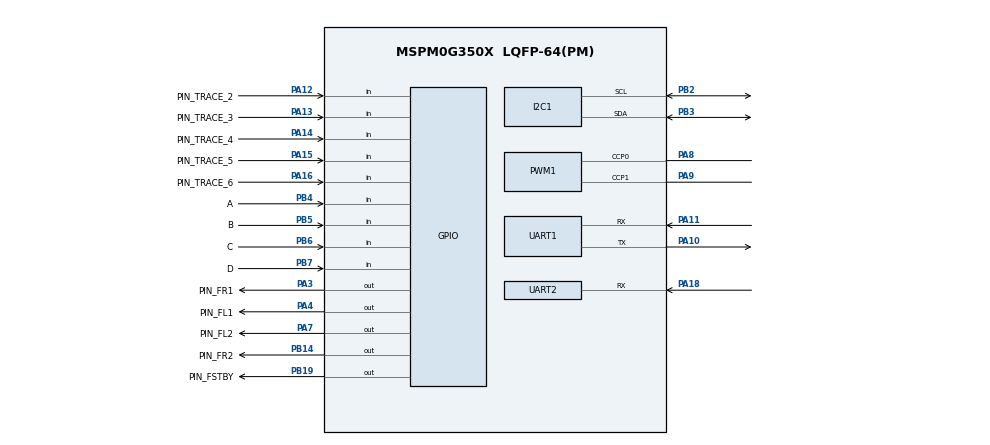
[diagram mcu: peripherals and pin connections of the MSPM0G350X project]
/**
 * These arguments were used when this file was generated. They will be automatically applied on subsequent loads
 * via the GUI or CLI. Run CLI with '--help' for additional information on how to override these arguments.
 * @cliArgs --device "MSPM0G350X" --package "LQFP-64(PM)" --part "Default" --product "mspm0_sdk@2.00.01.00"
 * @versions {"tool":"1.20.0+3587"}
 */

/**
 * Import the modules used in this configuration.
 */
const GPIO   = scripting.addModule("/ti/driverlib/GPIO", {}, false);
const GPIO1  = GPIO.addInstance();
const GPIO2  = GPIO.addInstance();
const GPIO3  = GPIO.addInstance();
const GPIO4  = GPIO.addInstance();
const GPIO5  = GPIO.addInstance();
const I2C    = scripting.addModule("/ti/driverlib/I2C", {}, false);
const I2C1   = I2C.addInstance();
const PWM    = scripting.addModule("/ti/driverlib/PWM", {}, false);
const PWM1   = PWM.addInstance();
const SYSCTL = scripting.addModule("/ti/driverlib/SYSCTL");
const TIMER  = scripting.addModule("/ti/driverlib/TIMER", {}, false);
const TIMER1 = TIMER.addInstance();
const TIMER2 = TIMER.addInstance();
const UART   = scripting.addModule("/ti/driverlib/UART", {}, false);
const UART1  = UART.addInstance();
const UART2  = UART.addInstance();
const UART3  = UART.addInstance();

/**
 * Write custom configuration values to the imported modules.
 */
const divider6       = system.clockTree["PLL_CLK2X_DIV"];
divider6.divideValue = 4;

const divider7       = system.clockTree["PLL_PDIV"];
divider7.divideValue = 2;

const divider9       = system.clockTree["UDIV"];
divider9.divideValue = 2;

const multiplier2         = system.clockTree["PLL_QDIV"];
multiplier2.multiplyValue = 10;

const mux4       = system.clockTree["EXHFMUX"];
mux4.inputSelect = "EXHFMUX_XTAL";

const mux8       = system.clockTree["HSCLKMUX"];
mux8.inputSelect = "HSCLKMUX_SYSPLL0";

const pinFunction4        = system.clockTree["HFXT"];
pinFunction4.enable       = true;
pinFunction4.HFCLKMonitor = true;
pinFunction4.inputFreq    = 40;
pinFunction4.HFXTStartup  = 20;

GPIO1.$name                              = "GPIO_SWITCH";
GPIO1.associatedPins[0].$name            = "USER_SWITCH_S2";
GPIO1.associatedPins[0].direction        = "INPUT";
GPIO1.associatedPins[0].assignedPort     = "PORTB";
GPIO1.associatedPins[0].assignedPin      = "21";
GPIO1.associatedPins[0].internalResistor = "PULL_UP";

const Board = scripting.addModule("/ti/driverlib/Board", {}, false);

GPIO2.$name                         = "GPIO_MOTOR";
GPIO2.associatedPins.create(5);
GPIO2.associatedPins[0].$name       = "PIN_FL2";
GPIO2.associatedPins[0].pin.$assign = "PA7";
GPIO2.associatedPins[1].$name       = "PIN_FL1";
GPIO2.associatedPins[1].pin.$assign = "PA4";
GPIO2.associatedPins[2].$name       = "PIN_FR1";
GPIO2.associatedPins[2].pin.$assign = "PA3";
GPIO2.associatedPins[3].$name       = "PIN_FR2";
GPIO2.associatedPins[3].pin.$assign = "PB14";
GPIO2.associatedPins[4].$name       = "PIN_FSTBY";
GPIO2.associatedPins[4].pin.$assign = "PB19";

GPIO3.$name                         = "GPIO_TRACE";
GPIO3.port                          = "PORTA";
GPIO3.associatedPins.create(8);
GPIO3.associatedPins[0].direction   = "INPUT";
GPIO3.associatedPins[0].$name       = "PIN_TRACE_0";
GPIO3.associatedPins[1].direction   = "INPUT";
GPIO3.associatedPins[1].$name       = "PIN_TRACE_1";
GPIO3.associatedPins[2].direction   = "INPUT";
GPIO3.associatedPins[2].$name       = "PIN_TRACE_2";
GPIO3.associatedPins[2].pin.$assign = "PA12";
GPIO3.associatedPins[3].direction   = "INPUT";
GPIO3.associatedPins[3].$name       = "PIN_TRACE_3";
GPIO3.associatedPins[3].pin.$assign = "PA13";
GPIO3.associatedPins[4].direction   = "INPUT";
GPIO3.associatedPins[4].$name       = "PIN_TRACE_4";
GPIO3.associatedPins[4].pin.$assign = "PA14";
GPIO3.associatedPins[5].direction   = "INPUT";
GPIO3.associatedPins[5].$name       = "PIN_TRACE_5";
GPIO3.associatedPins[5].pin.$assign = "PA15";
GPIO3.associatedPins[6].direction   = "INPUT";
GPIO3.associatedPins[6].$name       = "PIN_TRACE_6";
GPIO3.associatedPins[6].pin.$assign = "PA16";
GPIO3.associatedPins[7].direction   = "INPUT";
GPIO3.associatedPins[7].$name       = "PIN_TRACE_7";

GPIO4.$name                         = "GPIO_GW";
GPIO4.port                          = "PORTA";
GPIO4.associatedPins.create(2);
GPIO4.associatedPins[0].ioStructure = "OD";
GPIO4.associatedPins[0].$name       = "GPIO_SCL";
GPIO4.associatedPins[1].$name       = "GPIO_SDA";
GPIO4.associatedPins[1].ioStructure = "OD";

GPIO5.$name                               = "Encoder";
GPIO5.associatedPins.create(4);
GPIO5.associatedPins[0].direction         = "INPUT";
GPIO5.associatedPins[0].interruptEn       = true;
GPIO5.associatedPins[0].interruptPriority = "1";
GPIO5.associatedPins[0].polarity          = "RISE_FALL";
GPIO5.associatedPins[0].assignedPort      = "PORTB";
GPIO5.associatedPins[0].$name             = "A";
GPIO5.associatedPins[0].pin.$assign       = "PB4";
GPIO5.associatedPins[1].direction         = "INPUT";
GPIO5.associatedPins[1].interruptEn       = true;
GPIO5.associatedPins[1].interruptPriority = "1";
GPIO5.associatedPins[1].polarity          = "RISE_FALL";
GPIO5.associatedPins[1].assignedPort      = "PORTB";
GPIO5.associatedPins[1].$name             = "B";
GPIO5.associatedPins[1].pin.$assign       = "PB5";
GPIO5.associatedPins[2].direction         = "INPUT";
GPIO5.associatedPins[2].interruptEn       = true;
GPIO5.associatedPins[2].interruptPriority = "1";
GPIO5.associatedPins[2].polarity          = "RISE_FALL";
GPIO5.associatedPins[2].assignedPort      = "PORTB";
GPIO5.associatedPins[2].$name             = "C";
GPIO5.associatedPins[2].pin.$assign       = "PB6";
GPIO5.associatedPins[3].direction         = "INPUT";
GPIO5.associatedPins[3].assignedPort      = "PORTB";
GPIO5.associatedPins[3].interruptEn       = true;
GPIO5.associatedPins[3].interruptPriority = "1";
GPIO5.associatedPins[3].polarity          = "RISE_FALL";
GPIO5.associatedPins[3].$name             = "D";
GPIO5.associatedPins[3].pin.$assign       = "PB7";

I2C1.$name                             = "I2C_MPU6050";
I2C1.basicEnableController             = true;
I2C1.intController                     = ["ARBITRATION_LOST","NACK","RXFIFO_TRIGGER","RX_DONE","TX_DONE"];
I2C1.peripheral.$assign                = "I2C1";
I2C1.peripheral.sdaPin.$assign         = "PB3";
I2C1.peripheral.sclPin.$assign         = "PB2";
I2C1.sdaPinConfig.$name                = "ti_driverlib_gpio_GPIOPinGeneric0";
I2C1.sdaPinConfig.hideOutputInversion  = scripting.forceWrite(false);
I2C1.sdaPinConfig.onlyInternalResistor = scripting.forceWrite(false);
I2C1.sdaPinConfig.passedPeripheralType = scripting.forceWrite("Digital");
I2C1.sclPinConfig.$name                = "ti_driverlib_gpio_GPIOPinGeneric1";
I2C1.sclPinConfig.hideOutputInversion  = scripting.forceWrite(false);
I2C1.sclPinConfig.onlyInternalResistor = scripting.forceWrite(false);
I2C1.sclPinConfig.passedPeripheralType = scripting.forceWrite("Digital");

PWM1.$name                              = "PWM_MOTOR";
PWM1.timerCount                         = 3200;
PWM1.timerStartTimer                    = true;
PWM1.peripheral.$assign                 = "TIMA0";
PWM1.peripheral.ccp0Pin.$assign         = "PA8";
PWM1.peripheral.ccp1Pin.$assign         = "PA9";
PWM1.PWM_CHANNEL_0.$name                = "ti_driverlib_pwm_PWMTimerCC2";
PWM1.PWM_CHANNEL_0.ccValue              = 3199;
PWM1.PWM_CHANNEL_1.$name                = "ti_driverlib_pwm_PWMTimerCC3";
PWM1.PWM_CHANNEL_1.ccValue              = 3199;
PWM1.ccp0PinConfig.direction            = scripting.forceWrite("OUTPUT");
PWM1.ccp0PinConfig.hideOutputInversion  = scripting.forceWrite(false);
PWM1.ccp0PinConfig.onlyInternalResistor = scripting.forceWrite(false);
PWM1.ccp0PinConfig.passedPeripheralType = scripting.forceWrite("Digital");
PWM1.ccp0PinConfig.$name                = "ti_driverlib_gpio_GPIOPinGeneric12";
PWM1.ccp1PinConfig.direction            = scripting.forceWrite("OUTPUT");
PWM1.ccp1PinConfig.hideOutputInversion  = scripting.forceWrite(false);
PWM1.ccp1PinConfig.onlyInternalResistor = scripting.forceWrite(false);
PWM1.ccp1PinConfig.passedPeripheralType = scripting.forceWrite("Digital");
PWM1.ccp1PinConfig.$name                = "ti_driverlib_gpio_GPIOPinGeneric13";

SYSCTL.forceDefaultClkConfig = true;
SYSCTL.clockTreeEn           = true;

TIMER1.timerClkDiv        = 2;
TIMER1.interrupts         = ["ZERO"];
TIMER1.timerClkPrescale   = 10;
TIMER1.timerMode          = "PERIODIC";
TIMER1.$name              = "TIMER_1";
TIMER1.timerPeriod        = "1ms";
TIMER1.peripheral.$assign = "TIMG0";

TIMER2.$name              = "TIMER_2";
TIMER2.timerClkPrescale   = 200;
TIMER2.timerMode          = "PERIODIC";
TIMER2.timerPeriod        = "5ms";
TIMER2.interrupts         = ["ZERO"];
TIMER2.interruptPriority  = "2";
TIMER2.peripheral.$assign = "TIMG7";

UART1.$name                    = "UART_0";
UART1.targetBaudRate           = 115200;
UART1.enabledInterrupts        = ["RX"];
UART1.peripheral.rxPin.$assign = "PA11";
UART1.peripheral.txPin.$assign = "PA10";
UART1.txPinConfig.$name        = "ti_driverlib_gpio_GPIOPinGeneric4";
UART1.rxPinConfig.$name        = "ti_driverlib_gpio_GPIOPinGeneric5";

UART2.targetBaudRate                         = 115200;
UART2.enabledInterrupts                      = ["RX"];
UART2.$name                                  = "UART_SOC";
UART2.peripheral.rxPin.$assign               = "PA18";
UART2.peripheral.txPin.$assignAllowConflicts = "PA17";
UART2.txPinConfig.$name                      = "ti_driverlib_gpio_GPIOPinGeneric8";
UART2.txPinConfig.direction                  = scripting.forceWrite("OUTPUT");
UART2.txPinConfig.hideOutputInversion        = scripting.forceWrite(false);
UART2.txPinConfig.onlyInternalResistor       = scripting.forceWrite(false);
UART2.txPinConfig.passedPeripheralType       = scripting.forceWrite("Digital");
UART2.rxPinConfig.$name                      = "ti_driverlib_gpio_GPIOPinGeneric9";
UART2.rxPinConfig.hideOutputInversion        = scripting.forceWrite(false);
UART2.rxPinConfig.onlyInternalResistor       = scripting.forceWrite(false);
UART2.rxPinConfig.passedPeripheralType       = scripting.forceWrite("Digital");

UART3.$name                            = "UART_Screen";
UART3.targetBaudRate                   = 115200;
UART3.enabledInterrupts                = ["RX"];
UART3.rxFifoThreshold                  = "DL_UART_RX_FIFO_LEVEL_ONE_ENTRY";
UART3.txFifoThreshold                  = "DL_UART_TX_FIFO_LEVEL_ONE_ENTRY";
UART3.interruptPriority                = "0";
UART3.txPinConfig.$name                = "ti_driverlib_gpio_GPIOPinGeneric10";
UART3.txPinConfig.direction            = scripting.forceWrite("OUTPUT");
UART3.txPinConfig.hideOutputInversion  = scripting.forceWrite(false);
UART3.txPinConfig.onlyInternalResistor = scripting.forceWrite(false);
UART3.txPinConfig.passedPeripheralType = scripting.forceWrite("Digital");
UART3.rxPinConfig.$name                = "ti_driverlib_gpio_GPIOPinGeneric11";
UART3.rxPinConfig.hideOutputInversion  = scripting.forceWrite(false);
UART3.rxPinConfig.onlyInternalResistor = scripting.forceWrite(false);
UART3.rxPinConfig.passedPeripheralType = scripting.forceWrite("Digital");

/**
 * Pinmux solution for unlocked pins/peripherals. This ensures that minor changes to the automatic solver in a future
 * version of the tool will not impact the pinmux you originally saw.  These lines can be completely deleted in order to
 * re-solve from scratch.
 */
pinFunction4.peripheral.$suggestSolution           = "SYSCTL";
pinFunction4.peripheral.hfxInPin.$suggestSolution  = "PA5";
pinFunction4.peripheral.hfxOutPin.$suggestSolution = "PA6";
GPIO1.associatedPins[0].pin.$suggestSolution       = "PB21";
Board.peripheral.$suggestSolution                  = "DEBUGSS";
Board.peripheral.swclkPin.$suggestSolution         = "PA20";
Board.peripheral.swdioPin.$suggestSolution         = "PA19";
GPIO3.associatedPins[0].pin.$suggestSolution       = "PA25";
GPIO3.associatedPins[1].pin.$suggestSolution       = "PA24";
GPIO3.associatedPins[7].pin.$suggestSolution       = "PA23";
GPIO4.associatedPins[0].pin.$suggestSolution       = "PA1";
GPIO4.associatedPins[1].pin.$suggestSolution       = "PA0";
UART1.peripheral.$suggestSolution                  = "UART0";
UART2.peripheral.$suggestSolution                  = "UART1";
UART3.peripheral.$suggestSolution                  = "UART2";
UART3.peripheral.rxPin.$suggestSolution            = "PA22";
UART3.peripheral.txPin.$suggestSolution            = "PA21";
